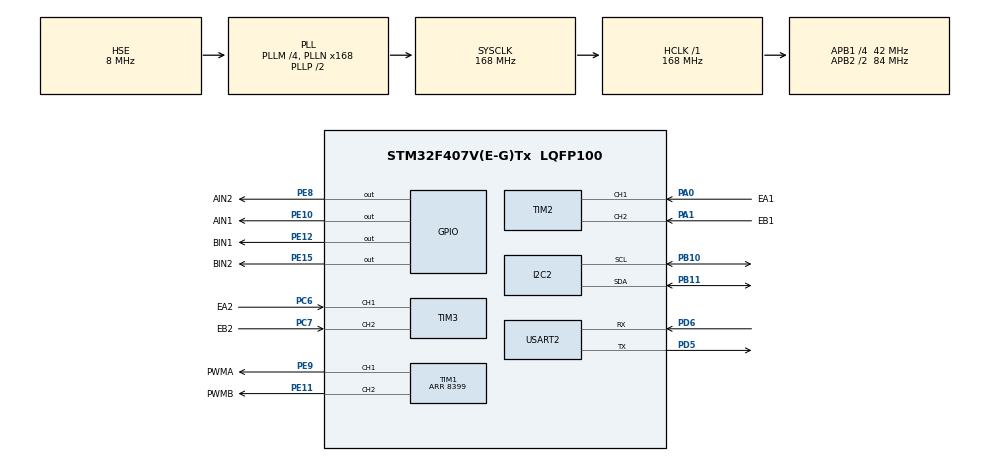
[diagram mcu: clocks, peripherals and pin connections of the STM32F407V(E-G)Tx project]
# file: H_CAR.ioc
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FREERTOS.Tasks01=defaultTask,24,128,StartDefaultTask,Default,NULL,Dynamic,NULL,NULL
Mcu.Family=STM32F4
Mcu.Name=STM32F407V(E-G)Tx
Mcu.Package=LQFP100
NVIC.PriorityGroup=NVIC_PRIORITYGROUP_4
NVIC.TIM4_IRQn=true\:5\:0\:false\:false\:true\:true\:true\:true\:true
NVIC.TIM5_IRQn=true\:15\:0\:false\:false\:true\:false\:false\:true\:true
NVIC.TimeBase=TIM5_IRQn
NVIC.TimeBaseIP=TIM5
NVIC.USART2_IRQn=true\:5\:0\:false\:false\:true\:true\:true\:true\:true
PA0-WKUP.GPIO_Label=EA1
PA0-WKUP.Signal=S_TIM2_CH1_ETR
PA1.GPIO_Label=EB1
PA1.Signal=S_TIM2_CH2
PA13.Mode=Serial_Wire
PA13.Signal=SYS_JTMS-SWDIO
PA14.Mode=Serial_Wire
PA14.Signal=SYS_JTCK-SWCLK
PB10.Mode=I2C
PB10.Signal=I2C2_SCL
PB11.Mode=I2C
PB11.Signal=I2C2_SDA
PC6.GPIO_Label=EA2
PC6.Signal=S_TIM3_CH1
PC7.GPIO_Label=EB2
PC7.Signal=S_TIM3_CH2
PD5.Mode=Asynchronous
PD5.Signal=USART2_TX
PD6.Mode=Asynchronous
PD6.Signal=USART2_RX
PE10.GPIO_Label=AIN1
PE10.Signal=GPIO_Output
PE11.GPIO_Label=PWMB
PE11.Signal=S_TIM1_CH2
PE12.GPIO_Label=BIN1
PE12.Signal=GPIO_Output
PE15.GPIO_Label=BIN2
PE15.Signal=GPIO_Output
PE8.GPIO_Label=AIN2
PE8.Signal=GPIO_Output
PE9.GPIO_Label=PWMA
PE9.Signal=S_TIM1_CH1
PH0-OSC_IN.Mode=HSE-External-Oscillator
PH0-OSC_IN.Signal=RCC_OSC_IN
PH1-OSC_OUT.Mode=HSE-External-Oscillator
PH1-OSC_OUT.Signal=RCC_OSC_OUT
ProjectManager.HeapSize=0x200
ProjectManager.StackSize=0x400
ProjectManager.TargetToolchain=Makefile
RCC.48MHZClocksFreq_Value=84000000
RCC.AHBFreq_Value=168000000
RCC.APB1CLKDivider=RCC_HCLK_DIV4
RCC.APB1Freq_Value=42000000
RCC.APB1TimFreq_Value=84000000
RCC.APB2CLKDivider=RCC_HCLK_DIV2
RCC.APB2Freq_Value=84000000
RCC.APB2TimFreq_Value=168000000
RCC.CortexFreq_Value=168000000
RCC.HCLKFreq_Value=168000000
RCC.HSE_VALUE=8000000
RCC.HSI_VALUE=16000000
RCC.LSE_VALUE=32768
RCC.PLLM=4
RCC.PLLN=168
RCC.PLLSourceVirtual=RCC_PLLSOURCE_HSE
RCC.SYSCLKFreq_VALUE=168000000
RCC.SYSCLKSource=RCC_SYSCLKSOURCE_PLLCLK
RCC.VCOOutputFreq_Value=336000000
SH.S_TIM1_CH1.0=TIM1_CH1,PWM Generation1 CH1
SH.S_TIM1_CH2.0=TIM1_CH2,PWM Generation2 CH2
SH.S_TIM2_CH1_ETR.0=TIM2_CH1,Encoder_Interface
SH.S_TIM2_CH2.0=TIM2_CH2,Encoder_Interface
SH.S_TIM3_CH1.0=TIM3_CH1,Encoder_Interface
SH.S_TIM3_CH2.0=TIM3_CH2,Encoder_Interface
TIM1.Channel-PWM\ Generation1\ CH1=TIM_CHANNEL_1
TIM1.Channel-PWM\ Generation2\ CH2=TIM_CHANNEL_2
TIM1.Period=8399
TIM2.EncoderMode=TIM_ENCODERMODE_TI12
TIM3.EncoderMode=TIM_ENCODERMODE_TI12
TIM4.Period=99
TIM4.Prescaler=8399
USART2.VirtualMode=VM_ASYNC
VP_FREERTOS_VS_CMSIS_V2.Mode=CMSIS_V2
VP_SYS_VS_tim5.Mode=TIM5
VP_TIM4_VS_ClockSourceINT.Mode=Internal
board=custom

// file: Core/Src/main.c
/* USER CODE BEGIN Header */
/**
  ******************************************************************************
  * @file           : main.c
  * @brief          : Main program body
  ******************************************************************************
  * @attention
  *
  * Copyright (c) 2026 STMicroelectronics.
  * All rights reserved.
  *
  * This software is licensed under terms that can be found in the LICENSE file
  * in the root directory of this software component.
  * If no LICENSE file comes with this software, it is provided AS-IS.
  *
  ******************************************************************************
  */
/* USER CODE END Header */
#include "main.h"
#include "cmsis_os.h"
#include "i2c.h"
#include "tim.h"
#include "usart.h"
#include "gpio.h"

/* USER CODE BEGIN Includes */
#include "app_task.h"

/* USER CODE END Includes */

void SystemClock_Config(void);
void MX_FREERTOS_Init(void);

int main(void)
{

  /* MCU Configuration--------------------------------------------------------*/

  /* Reset of all peripherals, Initializes the Flash interface and the Systick. */
  HAL_Init();

  /* Configure the system clock */
  SystemClock_Config();

  /* Initialize all configured peripherals */
  MX_GPIO_Init();
  MX_TIM1_Init();
  MX_TIM2_Init();
  MX_TIM3_Init();
  MX_USART2_UART_Init();
  MX_TIM4_Init();
  MX_I2C2_Init();
  /* USER CODE BEGIN 2 */
  User_Init();

  /* USER CODE END 2 */

  /* Init scheduler */
  osKernelInitialize();  /* Call init function for freertos objects (in cmsis_os2.c) */
  MX_FREERTOS_Init();

  /* Start scheduler */
  osKernelStart();

  /* We should never get here as control is now taken by the scheduler */

  /* Infinite loop */
  while (1)
  {

  }
}

void SystemClock_Config(void)
{
  RCC_OscInitTypeDef RCC_OscInitStruct = {0};
  RCC_ClkInitTypeDef RCC_ClkInitStruct = {0};

  /** Configure the main internal regulator output voltage
  */
  __HAL_RCC_PWR_CLK_ENABLE();
  __HAL_PWR_VOLTAGESCALING_CONFIG(PWR_REGULATOR_VOLTAGE_SCALE1);

  /** Initializes the RCC Oscillators according to the specified parameters
  * in the RCC_OscInitTypeDef structure.
  */
  RCC_OscInitStruct.OscillatorType = RCC_OSCILLATORTYPE_HSE;
  RCC_OscInitStruct.HSEState = RCC_HSE_ON;
  RCC_OscInitStruct.PLL.PLLState = RCC_PLL_ON;
  RCC_OscInitStruct.PLL.PLLSource = RCC_PLLSOURCE_HSE;
  RCC_OscInitStruct.PLL.PLLM = 4;
  RCC_OscInitStruct.PLL.PLLN = 168;
  RCC_OscInitStruct.PLL.PLLP = RCC_PLLP_DIV2;
  RCC_OscInitStruct.PLL.PLLQ = 4;
  if (HAL_RCC_OscConfig(&RCC_OscInitStruct) != HAL_OK)
  {
    Error_Handler();
  }

  /** Initializes the CPU, AHB and APB buses clocks
  */
  RCC_ClkInitStruct.ClockType = RCC_CLOCKTYPE_HCLK|RCC_CLOCKTYPE_SYSCLK
                              |RCC_CLOCKTYPE_PCLK1|RCC_CLOCKTYPE_PCLK2;
  RCC_ClkInitStruct.SYSCLKSource = RCC_SYSCLKSOURCE_PLLCLK;
  RCC_ClkInitStruct.AHBCLKDivider = RCC_SYSCLK_DIV1;
  RCC_ClkInitStruct.APB1CLKDivider = RCC_HCLK_DIV4;
  RCC_ClkInitStruct.APB2CLKDivider = RCC_HCLK_DIV2;

  if (HAL_RCC_ClockConfig(&RCC_ClkInitStruct, FLASH_LATENCY_5) != HAL_OK)
  {
    Error_Handler();
  }
}

void HAL_TIM_PeriodElapsedCallback(TIM_HandleTypeDef *htim)
{
  if (htim->Instance == TIM5)
  {
    HAL_IncTick();
  }
  /* USER CODE BEGIN Callback 1 */
  if (htim->Instance == TIM4)
  {
    App_Timer100HzISR();
  }

  /* USER CODE END Callback 1 */
}

void Error_Handler(void)
{
  __disable_irq();
  while (1)
  {
  }
}

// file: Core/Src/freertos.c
/* USER CODE BEGIN Header */
/**
  ******************************************************************************
  * File Name          : freertos.c
  * Description        : Code for freertos applications
  ******************************************************************************
  * @attention
  *
  * Copyright (c) 2026 STMicroelectronics.
  * All rights reserved.
  *
  * This software is licensed under terms that can be found in the LICENSE file
  * in the root directory of this software component.
  * If no LICENSE file comes with this software, it is provided AS-IS.
  *
  ******************************************************************************
  */
/* USER CODE END Header */

#include "FreeRTOS.h"
#include "task.h"
#include "main.h"
#include "cmsis_os.h"

/* USER CODE BEGIN Includes */
#include "app_task.h"

/* USER CODE END Includes */

/* Definitions for defaultTask */
osThreadId_t defaultTaskHandle;
const osThreadAttr_t defaultTask_attributes = {
  .name = "defaultTask",
  .stack_size = 128 * 4,
  .priority = (osPriority_t) osPriorityNormal,
};

void StartDefaultTask(void *argument);

void MX_FREERTOS_Init(void); /* (MISRA C 2004 rule 8.1) */

void MX_FREERTOS_Init(void) {

  /* Create the thread(s) */
  /* creation of defaultTask */
  defaultTaskHandle = osThreadNew(StartDefaultTask, NULL, &defaultTask_attributes);

  /* USER CODE BEGIN RTOS_THREADS */
  APP_FREERTOS_Init();
  /* USER CODE END RTOS_THREADS */

}

void StartDefaultTask(void *argument)
{
  for(;;)
  {
    osDelay(1);
  }
}
